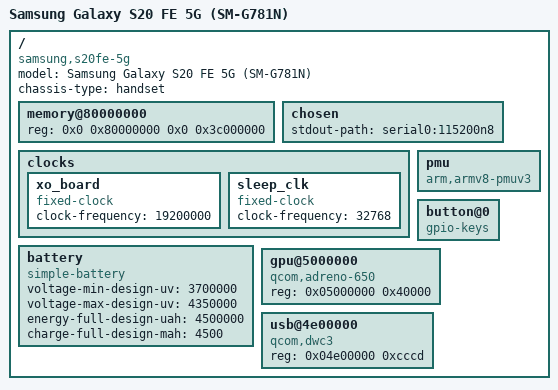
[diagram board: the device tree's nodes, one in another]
/*
 * Device Tree Source for Samsung Galaxy S20 FE 5G (SM-G781N)
 * Based on Qualcomm SM8250 (Snapdragon 865)
 *
 * Simplified standalone version - compiles without Qualcomm .dtsi includes
 * Reference: https://github.com/torvalds/linux/blob/master/arch/arm64/boot/dts/qcom/sm8250.dtsi
 */

/dts-v1/;

/ {
	model = "Samsung Galaxy S20 FE 5G (SM-G781N)";
	compatible = "samsung,s20fe-5g", "qcom,sm8250", "qcom,sdm865";
	chassis-type = "handset";

	#address-cells = <2>;
	#size-cells = <2>;

	memory@80000000 {
		device_type = "memory";
		reg = <0x0 0x80000000 0x0 0x3c000000>;
	};

	chosen {
		stdout-path = "serial0:115200n8";
	};

	clocks {
		xo_board: xo_board {
			compatible = "fixed-clock";
			clock-frequency = <19200000>;
			#clock-cells = <0>;
		};

		sleep_clk: sleep_clk {
			compatible = "fixed-clock";
			clock-frequency = <32768>;
			#clock-cells = <0>;
		};
	};

	pmu {
		compatible = "arm,armv8-pmuv3";
	};

	button@0 {
		compatible = "gpio-keys";
	};

	battery: battery {
		compatible = "simple-battery";
		voltage-min-design-uv = <3700000>;
		voltage-max-design-uv = <4350000>;
		energy-full-design-uah = <4500000>;
		charge-full-design-mah = <4500>;
	};

	/* GPU - Adreno 650 on SM8250 */
	gpu@5000000 {
		compatible = "qcom,adreno-650";
		reg = <0x05000000 0x40000>;
		reg-names = "kgsl_3d0_reg_memory";
		status = "okay";
	};

	/* USB Type-C */
	usb@4e00000 {
		compatible = "qcom,dwc3";
		reg = <0x04e00000 0xcccd>;
		status = "okay";
	};
};
